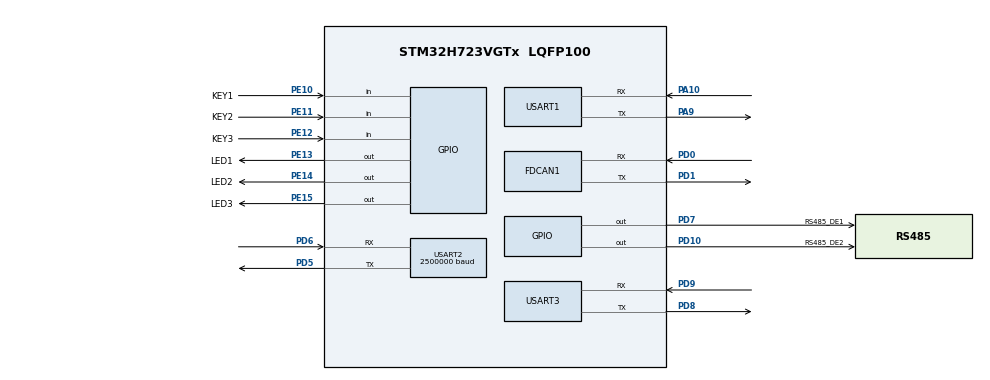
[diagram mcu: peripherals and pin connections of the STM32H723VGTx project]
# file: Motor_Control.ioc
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CORTEX_M7.default_mode_Activation=1
Dma.Request0=USART1_TX
Dma.Request1=USART1_RX
Dma.Request2=USART2_RX
Dma.Request3=USART2_TX
Dma.USART1_RX.1.Direction=DMA_PERIPH_TO_MEMORY
Dma.USART1_RX.1.EventEnable=DISABLE
Dma.USART1_RX.1.FIFOMode=DMA_FIFOMODE_DISABLE
Dma.USART1_RX.1.Instance=DMA1_Stream1
Dma.USART1_RX.1.MemDataAlignment=DMA_MDATAALIGN_BYTE
Dma.USART1_RX.1.MemInc=DMA_MINC_ENABLE
Dma.USART1_RX.1.Mode=DMA_NORMAL
Dma.USART1_RX.1.PeriphDataAlignment=DMA_PDATAALIGN_BYTE
Dma.USART1_RX.1.PeriphInc=DMA_PINC_DISABLE
Dma.USART1_RX.1.Polarity=HAL_DMAMUX_REQ_GEN_RISING
Dma.USART1_RX.1.Priority=DMA_PRIORITY_LOW
Dma.USART1_RX.1.RequestNumber=1
Dma.USART1_RX.1.SignalID=NONE
Dma.USART1_RX.1.SyncEnable=DISABLE
Dma.USART1_RX.1.SyncPolarity=HAL_DMAMUX_SYNC_NO_EVENT
Dma.USART1_RX.1.SyncRequestNumber=1
Dma.USART1_RX.1.SyncSignalID=NONE
Dma.USART1_TX.0.Direction=DMA_MEMORY_TO_PERIPH
Dma.USART1_TX.0.EventEnable=DISABLE
Dma.USART1_TX.0.FIFOMode=DMA_FIFOMODE_DISABLE
Dma.USART1_TX.0.Instance=DMA1_Stream0
Dma.USART1_TX.0.MemDataAlignment=DMA_MDATAALIGN_BYTE
Dma.USART1_TX.0.MemInc=DMA_MINC_ENABLE
Dma.USART1_TX.0.Mode=DMA_NORMAL
Dma.USART1_TX.0.PeriphDataAlignment=DMA_PDATAALIGN_BYTE
Dma.USART1_TX.0.PeriphInc=DMA_PINC_DISABLE
Dma.USART1_TX.0.Polarity=HAL_DMAMUX_REQ_GEN_RISING
Dma.USART1_TX.0.Priority=DMA_PRIORITY_LOW
Dma.USART1_TX.0.RequestNumber=1
Dma.USART1_TX.0.SignalID=NONE
Dma.USART1_TX.0.SyncEnable=DISABLE
Dma.USART1_TX.0.SyncPolarity=HAL_DMAMUX_SYNC_NO_EVENT
Dma.USART1_TX.0.SyncRequestNumber=1
Dma.USART1_TX.0.SyncSignalID=NONE
Dma.USART2_RX.2.Direction=DMA_PERIPH_TO_MEMORY
Dma.USART2_RX.2.EventEnable=DISABLE
Dma.USART2_RX.2.FIFOMode=DMA_FIFOMODE_DISABLE
Dma.USART2_RX.2.Instance=DMA1_Stream2
Dma.USART2_RX.2.MemDataAlignment=DMA_MDATAALIGN_BYTE
Dma.USART2_RX.2.MemInc=DMA_MINC_ENABLE
Dma.USART2_RX.2.Mode=DMA_NORMAL
Dma.USART2_RX.2.PeriphDataAlignment=DMA_PDATAALIGN_BYTE
Dma.USART2_RX.2.PeriphInc=DMA_PINC_DISABLE
Dma.USART2_RX.2.Polarity=HAL_DMAMUX_REQ_GEN_RISING
Dma.USART2_RX.2.Priority=DMA_PRIORITY_LOW
Dma.USART2_RX.2.RequestNumber=1
Dma.USART2_RX.2.SignalID=NONE
Dma.USART2_RX.2.SyncEnable=DISABLE
Dma.USART2_RX.2.SyncPolarity=HAL_DMAMUX_SYNC_NO_EVENT
Dma.USART2_RX.2.SyncRequestNumber=1
Dma.USART2_RX.2.SyncSignalID=NONE
Dma.USART2_TX.3.Direction=DMA_MEMORY_TO_PERIPH
Dma.USART2_TX.3.EventEnable=DISABLE
Dma.USART2_TX.3.FIFOMode=DMA_FIFOMODE_DISABLE
Dma.USART2_TX.3.Instance=DMA1_Stream3
Dma.USART2_TX.3.MemDataAlignment=DMA_MDATAALIGN_BYTE
Dma.USART2_TX.3.MemInc=DMA_MINC_ENABLE
Dma.USART2_TX.3.Mode=DMA_NORMAL
Dma.USART2_TX.3.PeriphDataAlignment=DMA_PDATAALIGN_BYTE
Dma.USART2_TX.3.PeriphInc=DMA_PINC_DISABLE
Dma.USART2_TX.3.Polarity=HAL_DMAMUX_REQ_GEN_RISING
Dma.USART2_TX.3.Priority=DMA_PRIORITY_LOW
Dma.USART2_TX.3.RequestNumber=1
Dma.USART2_TX.3.SignalID=NONE
Dma.USART2_TX.3.SyncEnable=DISABLE
Dma.USART2_TX.3.SyncPolarity=HAL_DMAMUX_SYNC_NO_EVENT
Dma.USART2_TX.3.SyncRequestNumber=1
Dma.USART2_TX.3.SyncSignalID=NONE
FDCAN1.AutoRetransmission=DISABLE
FDCAN1.CalculateBaudRateNominal=1000000
FDCAN1.CalculateTimeBitNominal=1000
FDCAN1.CalculateTimeQuantumNominal=25.0
FDCAN1.DataPrescaler=1
FDCAN1.DataTimeSeg1=1
FDCAN1.DataTimeSeg2=1
FDCAN1.ExtFiltersNbr=1
FDCAN1.FrameFormat=FDCAN_FRAME_CLASSIC
FDCAN1.Mode=FDCAN_MODE_NORMAL
FDCAN1.NominalPrescaler=2
FDCAN1.NominalSyncJumpWidth=8
FDCAN1.NominalTimeSeg1=31
FDCAN1.NominalTimeSeg2=8
FDCAN1.RxBuffersNbr=0
FDCAN1.RxFifo0ElmtsNbr=1
FDCAN1.RxFifo1ElmtsNbr=0
FDCAN1.TxFifoQueueElmtsNbr=1
Mcu.Family=STM32H7
Mcu.Name=STM32H723VGTx
Mcu.Package=LQFP100
NVIC.DMA1_Stream0_IRQn=true\:0\:0\:false\:false\:true\:false\:true\:true
NVIC.DMA1_Stream1_IRQn=true\:0\:0\:false\:false\:true\:false\:true\:true
NVIC.DMA1_Stream2_IRQn=true\:0\:0\:false\:false\:true\:false\:true\:true
NVIC.DMA1_Stream3_IRQn=true\:0\:0\:false\:false\:true\:false\:true\:true
NVIC.FDCAN1_IT0_IRQn=true\:0\:0\:false\:false\:true\:true\:true\:true
NVIC.PriorityGroup=NVIC_PRIORITYGROUP_4
NVIC.USART1_IRQn=true\:0\:0\:false\:false\:true\:true\:true\:true
NVIC.USART2_IRQn=true\:0\:0\:false\:false\:true\:true\:true\:true
NVIC.USART3_IRQn=true\:0\:0\:false\:false\:true\:true\:true\:true
PA10.Mode=Asynchronous
PA10.Signal=USART1_RX
PA9.Mode=Asynchronous
PA9.Signal=USART1_TX
PD0.GPIO_PuPd=GPIO_PULLUP
PD0.GPIO_Speed=GPIO_SPEED_FREQ_HIGH
PD0.Mode=FDCAN_Activate
PD0.Signal=FDCAN1_RX
PD1.GPIO_PuPd=GPIO_PULLUP
PD1.GPIO_Speed=GPIO_SPEED_FREQ_HIGH
PD1.Mode=FDCAN_Activate
PD1.Signal=FDCAN1_TX
PD10.GPIO_Label=RS485_DE2
PD10.GPIO_Speed=GPIO_SPEED_FREQ_HIGH
PD10.Signal=GPIO_Output
PD5.Mode=Asynchronous
PD5.Signal=USART2_TX
PD6.Mode=Asynchronous
PD6.Signal=USART2_RX
PD7.GPIO_Label=RS485_DE1
PD7.GPIO_Speed=GPIO_SPEED_FREQ_HIGH
PD7.PinState=GPIO_PIN_RESET
PD7.Signal=GPIO_Output
PD8.Mode=Asynchronous
PD8.Signal=USART3_TX
PD9.Mode=Asynchronous
PD9.Signal=USART3_RX
PE10.GPIO_Label=KEY1
PE10.GPIO_PuPd=GPIO_PULLUP
PE10.Signal=GPIO_Input
PE11.GPIO_Label=KEY2
PE11.GPIO_PuPd=GPIO_PULLUP
PE11.Signal=GPIO_Input
PE12.GPIO_Label=KEY3
PE12.GPIO_PuPd=GPIO_PULLUP
PE12.Signal=GPIO_Input
PE13.GPIO_Label=LED1
PE13.PinState=GPIO_PIN_SET
PE13.Signal=GPIO_Output
PE14.GPIO_Label=LED2
PE14.GPIO_PuPd=GPIO_NOPULL
PE14.PinState=GPIO_PIN_SET
PE14.Signal=GPIO_Output
PE15.GPIO_Label=LED3
PE15.PinState=GPIO_PIN_SET
PE15.Signal=GPIO_Output
PH0-OSC_IN.Mode=HSE-External-Oscillator
PH0-OSC_IN.Signal=RCC_OSC_IN
PH1-OSC_OUT.Mode=HSE-External-Oscillator
PH1-OSC_OUT.Signal=RCC_OSC_OUT
ProjectManager.HeapSize=0x200
ProjectManager.StackSize=0x400
ProjectManager.TargetToolchain=MDK-ARM V5.32
RCC.ADCFreq_Value=100000000
RCC.APB1Freq_Value=100000000
RCC.APB2Freq_Value=100000000
RCC.APB3Freq_Value=100000000
RCC.APB4Freq_Value=100000000
RCC.CortexFreq_Value=400000000
RCC.D1PPRE=RCC_APB3_DIV2
RCC.D2PPRE1=RCC_APB1_DIV2
RCC.D2PPRE2=RCC_APB2_DIV2
RCC.D3PPRE=RCC_APB4_DIV2
RCC.DIVM1=2
RCC.DIVM2=2
RCC.DIVN1=32
RCC.DIVN2=16
RCC.DIVP1=1
RCC.DIVQ1=5
RCC.DIVQ2=4
RCC.HCLKFreq_Value=200000000
RCC.HPRE=RCC_HCLK_DIV2
RCC.PLL2FRACN=0
RCC.PLL3FRACN=0
RCC.PLLFRACN=0
RCC.PLLSourceVirtual=RCC_PLLSOURCE_HSE
RCC.SYSCLKFreq_VALUE=400000000
RCC.SYSCLKSource=RCC_SYSCLKSOURCE_PLLCLK
RCC.USBFreq_Value=80000000
USART1.VirtualMode-Asynchronous=VM_ASYNC
USART2.BaudRate=2500000
USART2.VirtualMode-Asynchronous=VM_ASYNC
USART3.VirtualMode-Asynchronous=VM_ASYNC
VP_MEMORYMAP_VS_MEMORYMAP.Mode=CurAppReg
board=custom

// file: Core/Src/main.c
/* USER CODE BEGIN Header */
/**
  ******************************************************************************
  * @file           : main.c
  * @brief          : Main program body
  ******************************************************************************
  * @attention
  *
  * Copyright (c) 2026 STMicroelectronics.
  * All rights reserved.
  *
  * This software is licensed under terms that can be found in the LICENSE file
  * in the root directory of this software component.
  * If no LICENSE file comes with this software, it is provided AS-IS.
  *
  ******************************************************************************
  */
/* USER CODE END Header */
#include "main.h"
#include "dma.h"
#include "fdcan.h"
#include "usart.h"
#include "gpio.h"

/* USER CODE BEGIN Includes */
#include <string.h>
#include <stdio.h>
/* USER CODE END Includes */

void SystemClock_Config(void);
static void MPU_Config(void);

int main(void)
{

  /* MPU Configuration--------------------------------------------------------*/
  MPU_Config();

  /* MCU Configuration--------------------------------------------------------*/

  /* Reset of all peripherals, Initializes the Flash interface and the Systick. */
  HAL_Init();

  /* Configure the system clock */
  SystemClock_Config();

  /* Initialize all configured peripherals */
  MX_GPIO_Init();
  MX_DMA_Init();
  MX_USART1_UART_Init();
  MX_FDCAN1_Init();
  MX_USART2_UART_Init();
  MX_USART3_UART_Init();

  /* Infinite loop */
  while (1)
  {

  }
}

void SystemClock_Config(void)
{
  RCC_OscInitTypeDef RCC_OscInitStruct = {0};
  RCC_ClkInitTypeDef RCC_ClkInitStruct = {0};

  /** Supply configuration update enable
  */
  HAL_PWREx_ConfigSupply(PWR_LDO_SUPPLY);

  /** Configure the main internal regulator output voltage
  */
  __HAL_PWR_VOLTAGESCALING_CONFIG(PWR_REGULATOR_VOLTAGE_SCALE1);

  while(!__HAL_PWR_GET_FLAG(PWR_FLAG_VOSRDY)) {}

  /** Initializes the RCC Oscillators according to the specified parameters
  * in the RCC_OscInitTypeDef structure.
  */
  RCC_OscInitStruct.OscillatorType = RCC_OSCILLATORTYPE_HSE;
  RCC_OscInitStruct.HSEState = RCC_HSE_ON;
  RCC_OscInitStruct.PLL.PLLState = RCC_PLL_ON;
  RCC_OscInitStruct.PLL.PLLSource = RCC_PLLSOURCE_HSE;
  RCC_OscInitStruct.PLL.PLLM = 2;
  RCC_OscInitStruct.PLL.PLLN = 32;
  RCC_OscInitStruct.PLL.PLLP = 1;
  RCC_OscInitStruct.PLL.PLLQ = 5;
  RCC_OscInitStruct.PLL.PLLR = 2;
  RCC_OscInitStruct.PLL.PLLRGE = RCC_PLL1VCIRANGE_3;
  RCC_OscInitStruct.PLL.PLLVCOSEL = RCC_PLL1VCOWIDE;
  RCC_OscInitStruct.PLL.PLLFRACN = 0;
  if (HAL_RCC_OscConfig(&RCC_OscInitStruct) != HAL_OK)
  {
    Error_Handler();
  }

  /** Initializes the CPU, AHB and APB buses clocks
  */
  RCC_ClkInitStruct.ClockType = RCC_CLOCKTYPE_HCLK|RCC_CLOCKTYPE_SYSCLK
                              |RCC_CLOCKTYPE_PCLK1|RCC_CLOCKTYPE_PCLK2
                              |RCC_CLOCKTYPE_D3PCLK1|RCC_CLOCKTYPE_D1PCLK1;
  RCC_ClkInitStruct.SYSCLKSource = RCC_SYSCLKSOURCE_PLLCLK;
  RCC_ClkInitStruct.SYSCLKDivider = RCC_SYSCLK_DIV1;
  RCC_ClkInitStruct.AHBCLKDivider = RCC_HCLK_DIV2;
  RCC_ClkInitStruct.APB3CLKDivider = RCC_APB3_DIV2;
  RCC_ClkInitStruct.APB1CLKDivider = RCC_APB1_DIV2;
  RCC_ClkInitStruct.APB2CLKDivider = RCC_APB2_DIV2;
  RCC_ClkInitStruct.APB4CLKDivider = RCC_APB4_DIV2;

  if (HAL_RCC_ClockConfig(&RCC_ClkInitStruct, FLASH_LATENCY_2) != HAL_OK)
  {
    Error_Handler();
  }
}

/* USER CODE BEGIN 4 */

void HAL_FDCAN_ErrorCallback(FDCAN_HandleTypeDef *hfdcan)
{
    /* HAL FDCAN Error callback uses only the handle; read error via HAL_FDCAN_GetError */
    uint32_t Error = HAL_FDCAN_GetError(hfdcan);
    char buf[64];
    int len = snprintf(buf, sizeof(buf), "FDCAN Error: 0x%08lX\r\n", (unsigned long)Error);
    HAL_UART_Transmit_DMA(&huart1, (uint8_t*)buf, len);
    // Toggle LED3 to indicate error
    HAL_GPIO_TogglePin(GPIOE, LED3_Pin);
}

/* USER CODE END 4 */

 /* MPU Configuration */

void MPU_Config(void)
{
  MPU_Region_InitTypeDef MPU_InitStruct = {0};

  /* Disables the MPU */
  HAL_MPU_Disable();

  /** Initializes and configures the Region and the memory to be protected
  */
  MPU_InitStruct.Enable = MPU_REGION_ENABLE;
  MPU_InitStruct.Number = MPU_REGION_NUMBER0;
  MPU_InitStruct.BaseAddress = 0x0;
  MPU_InitStruct.Size = MPU_REGION_SIZE_4GB;
  MPU_InitStruct.SubRegionDisable = 0x87;
  MPU_InitStruct.TypeExtField = MPU_TEX_LEVEL0;
  MPU_InitStruct.AccessPermission = MPU_REGION_NO_ACCESS;
  MPU_InitStruct.DisableExec = MPU_INSTRUCTION_ACCESS_DISABLE;
  MPU_InitStruct.IsShareable = MPU_ACCESS_SHAREABLE;
  MPU_InitStruct.IsCacheable = MPU_ACCESS_NOT_CACHEABLE;
  MPU_InitStruct.IsBufferable = MPU_ACCESS_NOT_BUFFERABLE;

  HAL_MPU_ConfigRegion(&MPU_InitStruct);
  /* Enables the MPU */
  HAL_MPU_Enable(MPU_PRIVILEGED_DEFAULT);

}

void Error_Handler(void)
{
  __disable_irq();
  while (1)
  {
  }
}
